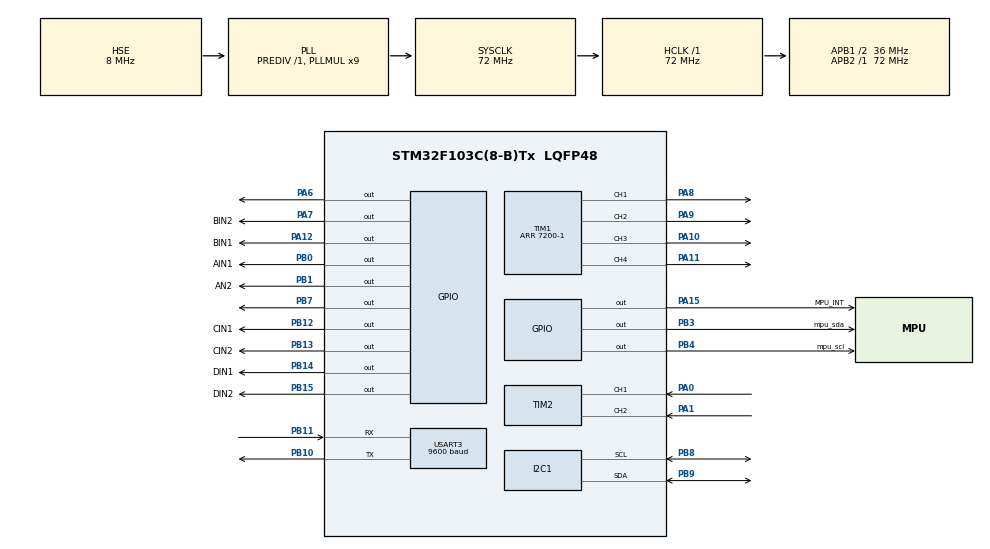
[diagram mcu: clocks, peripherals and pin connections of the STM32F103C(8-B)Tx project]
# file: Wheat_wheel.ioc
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Mcu.Family=STM32F1
Mcu.Name=STM32F103C(8-B)Tx
Mcu.Package=LQFP48
NVIC.PriorityGroup=NVIC_PRIORITYGROUP_4
NVIC.USART3_IRQn=true\:0\:0\:false\:false\:true\:true\:true\:true
PA0-WKUP.Signal=S_TIM2_CH1_ETR
PA1.Signal=S_TIM2_CH2
PA10.Signal=S_TIM1_CH3
PA11.Signal=S_TIM1_CH4
PA12.GPIO_Label=BIN1
PA12.GPIO_PuPd=GPIO_PULLUP
PA12.Signal=GPIO_Output
PA13.Mode=Serial_Wire
PA13.Signal=SYS_JTMS-SWDIO
PA14.Mode=Serial_Wire
PA14.Signal=SYS_JTCK-SWCLK
PA15.GPIO_Label=MPU_INT
PA15.GPIO_PuPd=GPIO_PULLUP
PA15.Signal=GPIO_Output
PA6.GPIO_PuPd=GPIO_PULLUP
PA6.Signal=GPIO_Output
PA7.GPIO_Label=BIN2
PA7.GPIO_PuPd=GPIO_PULLUP
PA7.Signal=GPIO_Output
PA8.Signal=S_TIM1_CH1
PA9.Signal=S_TIM1_CH2
PB0.GPIO_Label=AIN1
PB0.GPIO_PuPd=GPIO_PULLUP
PB0.Signal=GPIO_Output
PB1.GPIO_Label=AN2
PB1.GPIO_PuPd=GPIO_PULLUP
PB1.Signal=GPIO_Output
PB10.Mode=Asynchronous
PB10.Signal=USART3_TX
PB11.Mode=Asynchronous
PB11.Signal=USART3_RX
PB12.GPIO_Label=CIN1
PB12.GPIO_PuPd=GPIO_PULLUP
PB12.Signal=GPIO_Output
PB13.GPIO_Label=CIN2
PB13.GPIO_PuPd=GPIO_PULLUP
PB13.Signal=GPIO_Output
PB14.GPIO_Label=DIN1
PB14.GPIO_PuPd=GPIO_PULLUP
PB14.Signal=GPIO_Output
PB15.GPIO_Label=DIN2
PB15.GPIO_PuPd=GPIO_PULLUP
PB15.Signal=GPIO_Output
PB3.GPIO_Label=mpu_sda
PB3.GPIO_PuPd=GPIO_PULLUP
PB3.Signal=GPIO_Output
PB4.GPIO_Label=mpu_scl
PB4.GPIO_PuPd=GPIO_PULLUP
PB4.Signal=GPIO_Output
PB7.GPIO_PuPd=GPIO_PULLUP
PB7.Signal=GPIO_Output
PB8.Mode=I2C
PB8.Signal=I2C1_SCL
PB9.Mode=I2C
PB9.Signal=I2C1_SDA
PC14-OSC32_IN.Mode=LSE-External-Oscillator
PC14-OSC32_IN.Signal=RCC_OSC32_IN
PC15-OSC32_OUT.Mode=LSE-External-Oscillator
PC15-OSC32_OUT.Signal=RCC_OSC32_OUT
PD0-OSC_IN.Mode=HSE-External-Oscillator
PD0-OSC_IN.Signal=RCC_OSC_IN
PD1-OSC_OUT.Mode=HSE-External-Oscillator
PD1-OSC_OUT.Signal=RCC_OSC_OUT
ProjectManager.HeapSize=0x200
ProjectManager.StackSize=0x400
ProjectManager.TargetToolchain=MDK-ARM V5.32
RCC.AHBFreq_Value=72000000
RCC.APB1CLKDivider=RCC_HCLK_DIV2
RCC.APB1Freq_Value=36000000
RCC.APB1TimFreq_Value=72000000
RCC.APB2Freq_Value=72000000
RCC.APB2TimFreq_Value=72000000
RCC.HCLKFreq_Value=72000000
RCC.PLLMUL=RCC_PLL_MUL9
RCC.PLLSourceVirtual=RCC_PLLSOURCE_HSE
RCC.SYSCLKFreq_VALUE=72000000
RCC.SYSCLKSource=RCC_SYSCLKSOURCE_PLLCLK
RCC.USBFreq_Value=72000000
SH.S_TIM1_CH1.0=TIM1_CH1,PWM Generation1 CH1
SH.S_TIM1_CH2.0=TIM1_CH2,PWM Generation2 CH2
SH.S_TIM1_CH3.0=TIM1_CH3,PWM Generation3 CH3
SH.S_TIM1_CH4.0=TIM1_CH4,PWM Generation4 CH4
SH.S_TIM2_CH1_ETR.0=TIM2_CH1,Encoder_Interface
SH.S_TIM2_CH2.0=TIM2_CH2,Encoder_Interface
TIM1.Channel-PWM\ Generation1\ CH1=TIM_CHANNEL_1
TIM1.Channel-PWM\ Generation2\ CH2=TIM_CHANNEL_2
TIM1.Channel-PWM\ Generation3\ CH3=TIM_CHANNEL_3
TIM1.Channel-PWM\ Generation4\ CH4=TIM_CHANNEL_4
TIM1.Period=7200-1
TIM1.Pulse-PWM\ Generation1\ CH1=7199
TIM1.Pulse-PWM\ Generation2\ CH2=7199
TIM1.Pulse-PWM\ Generation3\ CH3=7199
TIM1.Pulse-PWM\ Generation4\ CH4=7199
TIM2.EncoderMode=TIM_ENCODERMODE_TI12
USART3.BaudRate=9600
USART3.VirtualMode=VM_ASYNC
board=custom

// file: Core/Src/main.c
/* USER CODE BEGIN Header */
/**
  ******************************************************************************
  * @file           : main.c
  * @brief          : Main program body
  ******************************************************************************
  * @attention
  *
  * Copyright (c) 2024 STMicroelectronics.
  * All rights reserved.
  *
  * This software is licensed under terms that can be found in the LICENSE file
  * in the root directory of this software component.
  * If no LICENSE file comes with this software, it is provided AS-IS.
  *
  ******************************************************************************
  */
/* USER CODE END Header */
#include "main.h"
#include "i2c.h"
#include "tim.h"
#include "usart.h"
#include "gpio.h"
#include "encoder.h"

/* USER CODE BEGIN PV */
extern uint8_t rx_data[2];
uint8_t tx_data[2];
float pitch,roll,yaw;
int8_t step;
/* USER CODE END PV */

void SystemClock_Config(void);

int main(void)
{

  /* MCU Configuration--------------------------------------------------------*/

  /* Reset of all peripherals, Initializes the Flash interface and the Systick. */
  HAL_Init();

  /* Configure the system clock */
  SystemClock_Config();

  /* Initialize all configured peripherals */
  MX_GPIO_Init();
  MX_TIM1_Init();
  MX_USART3_UART_Init();
  MX_I2C1_Init();
  MX_TIM2_Init();

  /* Infinite loop */
  /* USER CODE BEGIN WHILE */
//	mpu_dmp_init();
//	MPU_Init();

	Motor_Init();
	JDY_31_Init(&huart3,rx_data,1);
	Encoder_Init(&htim2);

  while (1)
  {

		Read();
//		HAL_Delay(1);
//		mpu_dmp_get_data(&pitch,&roll,&yaw);
//		tx_data[0]=pitch;
//		HAL_UART_Transmit(&huart3,tx_data,sizeof(tx_data),10);

    /* USER CODE END WHILE */

  }
}

void SystemClock_Config(void)
{
  RCC_OscInitTypeDef RCC_OscInitStruct = {0};
  RCC_ClkInitTypeDef RCC_ClkInitStruct = {0};

  /** Initializes the RCC Oscillators according to the specified parameters
  * in the RCC_OscInitTypeDef structure.
  */
  RCC_OscInitStruct.OscillatorType = RCC_OSCILLATORTYPE_HSE;
  RCC_OscInitStruct.HSEState = RCC_HSE_ON;
  RCC_OscInitStruct.HSEPredivValue = RCC_HSE_PREDIV_DIV1;
  RCC_OscInitStruct.HSIState = RCC_HSI_ON;
  RCC_OscInitStruct.PLL.PLLState = RCC_PLL_ON;
  RCC_OscInitStruct.PLL.PLLSource = RCC_PLLSOURCE_HSE;
  RCC_OscInitStruct.PLL.PLLMUL = RCC_PLL_MUL9;
  if (HAL_RCC_OscConfig(&RCC_OscInitStruct) != HAL_OK)
  {
    Error_Handler();
  }

  /** Initializes the CPU, AHB and APB buses clocks
  */
  RCC_ClkInitStruct.ClockType = RCC_CLOCKTYPE_HCLK|RCC_CLOCKTYPE_SYSCLK
                              |RCC_CLOCKTYPE_PCLK1|RCC_CLOCKTYPE_PCLK2;
  RCC_ClkInitStruct.SYSCLKSource = RCC_SYSCLKSOURCE_PLLCLK;
  RCC_ClkInitStruct.AHBCLKDivider = RCC_SYSCLK_DIV1;
  RCC_ClkInitStruct.APB1CLKDivider = RCC_HCLK_DIV2;
  RCC_ClkInitStruct.APB2CLKDivider = RCC_HCLK_DIV1;

  if (HAL_RCC_ClockConfig(&RCC_ClkInitStruct, FLASH_LATENCY_2) != HAL_OK)
  {
    Error_Handler();
  }
}

void Error_Handler(void)
{
  __disable_irq();
  while (1)
  {
  }
}
